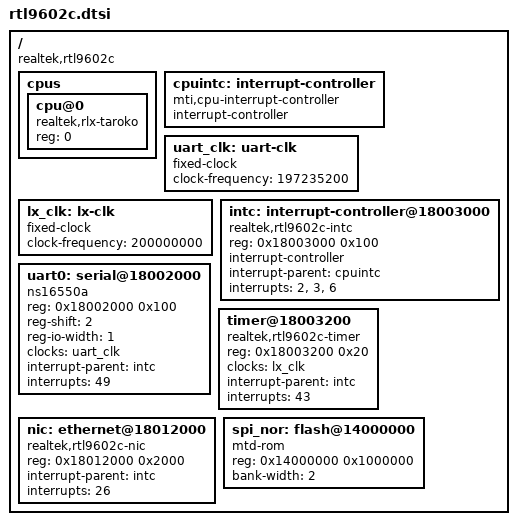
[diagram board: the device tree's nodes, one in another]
// SPDX-License-Identifier: GPL-2.0-or-later
/*
 * Realtek RTL9602C "Europa" GPON ONU SoC (RLX "Taroko" core).
 *
 * Clean-room device description derived from observed hardware facts
 * (register bases, IRQ numbers and clocks read from a running unit by
 * probing the live device).
 */

/ {
	#address-cells = <1>;
	#size-cells = <1>;
	compatible = "realtek,rtl9602c";

	cpus {
		#address-cells = <1>;
		#size-cells = <0>;

		cpu@0 {
			device_type = "cpu";
			compatible = "realtek,rlx-taroko";
			reg = <0>;
		};
	};

	cpuintc: interrupt-controller {
		#address-cells = <0>;
		#interrupt-cells = <1>;
		interrupt-controller;
		compatible = "mti,cpu-interrupt-controller";
	};

	/*
	 * SoC clocks (fixed): CPU 625 MHz, MEM 525 MHz, LX (bus) 200 MHz,
	 * SPI-F 50 MHz. The 16550 UART is fed from a 197.2352 MHz reference
	 * (base_baud 12327200 x 16).
	 */
	uart_clk: uart-clk {
		compatible = "fixed-clock";
		#clock-cells = <0>;
		clock-frequency = <197235200>;
	};

	/* LX (peripheral) bus clock, 200 MHz; feeds the SoC TC timer. */
	lx_clk: lx-clk {
		compatible = "fixed-clock";
		#clock-cells = <0>;
		clock-frequency = <200000000>;
	};

	intc: interrupt-controller@18003000 {
		compatible = "realtek,rtl9602c-intc";
		reg = <0x18003000 0x100>;
		interrupt-controller;
		#interrupt-cells = <1>;
		interrupt-parent = <&cpuintc>;
		/*
		 * The aggregator routes each input (GIRR nibble = target CP0 HW
		 * IRQ) onto one of several CP0 lines, not just line 2: the loaded
		 * routing uses values 2, 3 and 6 (e.g. the SoC timer is on 6).
		 * Cascade the dispatch on every CP0 line the routing targets so
		 * those interrupts are delivered (the dispatch scans all GISR
		 * words regardless of which line woke it).
		 */
		interrupts = <2>, <3>, <6>;
	};

	uart0: serial@18002000 {
		compatible = "ns16550a";
		reg = <0x18002000 0x100>;
		reg-shift = <2>;
		reg-io-width = <1>;
		clocks = <&uart_clk>;
		interrupt-parent = <&intc>;
		interrupts = <49>;
		status = "okay";
	};

	timer@18003200 {
		/*
		 * SoC "rlx timer" channel TC0 (CP0 Count is unreliable on this
		 * core, so this drives the system tick). The TC register block is
		 * at 0x18003200 (TC0 DATA/CNT/CTL/INT at +0x00/+0x04/+0x08/+0x0c);
		 * 0x18003100 is a different block whose +0x00 happens to be
		 * writable, which is why the earlier base accepted the reload
		 * write yet the control/interrupt writes never stuck.
		 */
		compatible = "realtek,rtl9602c-timer";
		reg = <0x18003200 0x20>;
		clocks = <&lx_clk>;
		interrupt-parent = <&intc>;
		interrupts = <43>;
	};
	nic: ethernet@18012000 {
		/* re8686-class GMAC0; base confirmed on silicon (IDR0-5 hold the
		 * U-Boot MAC). INTC input 26 = GMAC0 TX/RX completion (matches live
		 * stock GIMR0/GISR0 bit26 and /proc/interrupts "26: ... eth0"). The
		 * driver request_irq()s this for IRQ-driven NAPI TX/RX servicing. */
		compatible = "realtek,rtl9602c-nic";
		reg = <0x18012000 0x2000>;
		interrupt-parent = <&intc>;
		interrupts = <26>;
		status = "okay";
	};

	spi_nor: flash@14000000 {
		/* 16 MB SPI-NOR, memory-mapped (physmap) at 0x14000000 */
		compatible = "mtd-rom";
		reg = <0x14000000 0x1000000>;
		bank-width = <2>;
		#address-cells = <1>;
		#size-cells = <1>;
	};
};
